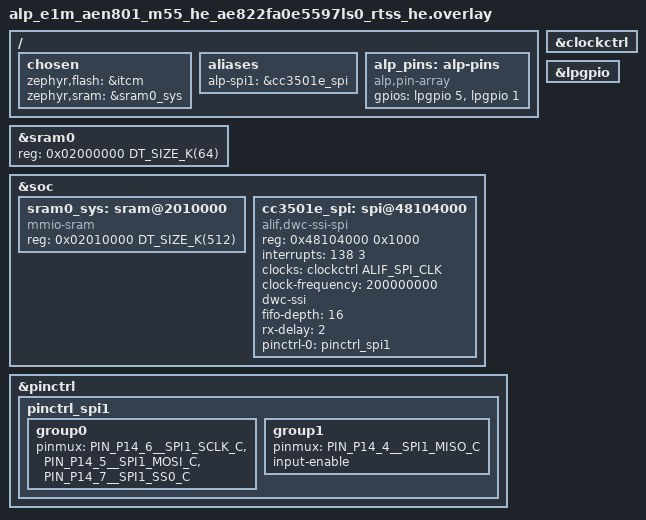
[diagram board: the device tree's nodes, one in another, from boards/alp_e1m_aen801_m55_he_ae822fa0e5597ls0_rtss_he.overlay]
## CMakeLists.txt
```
# SPDX-License-Identifier: Apache-2.0
#
# aen-cc3501e-socket-throughput -- measures CC3501E end-to-end TCP socket
# throughput over a correctly-sized window on the E1M-AEN801 (Ensemble E8,
# M55-HE). See src/main.c for why the window has to be this big.
#
# Standalone Zephyr app (no alp_project.py board.yaml flow), same shape as
# its closest sibling aen-cc3501e-command-sweep: build with
#   ZEPHYR_BASE=<zephyr-base> west build \
#     -b alp_e1m_aen801_m55_he/ae822fa0e5597ls0/rtss_he <this-dir> -- \
#     "-DEXTRA_ZEPHYR_MODULES=<alp-sdk>;<hal_alif>"
# Zephyr applies boards/<fully-qualified-board>.overlay by itself.

cmake_minimum_required(VERSION 3.20)

find_package(Zephyr REQUIRED HINTS $ENV{ZEPHYR_BASE})
project(aen_cc3501e_socket_throughput LANGUAGES C)

target_sources(app PRIVATE src/main.c)
# The SoM bring-up TEMPLATE (see its own header comment): opens the
# inter-chip SPI1 bridge + WIFI_EN/nRESET, enables the LP-pad output
# drivers pinctrl does not reach, binds the READY line, and runs the
# power + reset sequence. Copied verbatim from aen-cc3501e-command-sweep --
# byte-identical to the copies in every other aen-cc3501e-* sibling, same
# reasoning: a copyable template, not a cross-example reach-in.
target_sources(app PRIVATE src/cc3501e_bridge.c)
```

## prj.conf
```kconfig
# SPDX-License-Identifier: Apache-2.0
#
# Bench config for the CC3501E socket-throughput measurement on the
# E1M-AEN801 (Alif Ensemble E8, M55-HE). See src/main.c for what is measured
# and why the window is sized the way it is.

# --- Console -----------------------------------------------------------------
# Console: Alp UART console -- E1M edge UART0 (Alif UART5, P3_4/P3_5, 115200
# 8N1, NS16550), the E1M-AEN801 carrier console. The board _defconfig already
# selects it; set explicitly here so the app is self-describing.
CONFIG_SERIAL=y
CONFIG_CONSOLE=y
CONFIG_UART_CONSOLE=y
CONFIG_UART_INTERRUPT_DRIVEN=y
# Serial-less bench? Comment the four lines above and uncomment these to read
# 'ram_console_buf' over SWD instead -- the same toggle every sibling AEN
# bench app documents (see aen-rtc-tick-probe's prj.conf for the fuller note):
# CONFIG_RAM_CONSOLE=y
# CONFIG_RAM_CONSOLE_BUFFER_SIZE=4096
# CONFIG_UART_CONSOLE=n
CONFIG_PRINTK=y

# --- CC3501E bridge (SPI1 + WIFI_EN/nRESET/READY GPIOs) -----------------------
# The host-side chip driver (chips/cc3501e/*.c) plus the two peripheral
# classes it rides on: SPI for the inter-chip link (bus 1 -> the alp-spi1
# alias this app's overlay adds) and GPIO for WIFI_EN / nRESET / READY.
# Kconfig already enforces `depends on SPI && GPIO`; both are set explicitly
# here because this app has no board.yaml `peripherals:` block to generate
# them -- it is a standalone Zephyr app (see scripts/gen_example_alp_conf.py), same as
# aen-cc3501e-command-sweep. CONFIG_ALP_SDK_CHIP_CC3501E pulls in every
# chips/cc3501e/*.c TU (wifi/sockets/ble/gpio/spi/camera/power/ota/events),
# so this app can call cc3501e_wifi_connect()/cc3501e_sock_*() directly with
# no further Kconfig -- it never routes through the portable <alp/wifi.h>
# backend (CONFIG_ALP_SDK_WIFI_CC3501E), which attaches a DIFFERENT set of
# TUs this app has no use for.
CONFIG_SPI=y
CONFIG_GPIO=y
CONFIG_ALP_SDK=y
CONFIG_ALP_SDK_CHIP_CC3501E=y
# Pack 2 bytes per SPI FIFO slot on the polled bulk phases (#1725). The
# polled loop's MMIO accesses, not the 25 MHz wire, bound the bridge; the
# bits on the wire are identical. aen-cc3501e-bringup carries the same line.
CONFIG_SPI_DW_ALIF_PACK32=y

# CONFIG_ALP_SDK=y above defaults CONFIG_ALP_SDK_CONSOLE (zephyr/kconfigs/
# core.kconfig) to `y`, which `select`s CONFIG_SHELL -- pulling a `uart:~$`
# shell prompt into the middle of this app's own throughput transcript. This
# app never registers a shell command and never uses the `alp` console tree,
# so turn the console off explicitly rather than let its default drag the
# shell in unasked.
CONFIG_ALP_SDK_CONSOLE=n

# main()'s own locals + the HTTP header-scan state stay small: the recv
# buffer (SOCKTP_RECV_CEILING bytes, ~4 KB) and the cc3501e_t bridge handle
# (~32 KB, embeds several ALP_CC3501E_MAX_PAYLOAD scratch buffers) are BOTH
# STATIC in src/main.c, not automatic -- see that file's own header for why
# that discipline is load-bearing here, not optional: a sibling app in this
# tree died on its own prologue for exactly the mistake this app avoids by
# construction. 4096 matches aen-cc3501e-companion-tour, the other sibling
# that calls the socket API with the same static discipline.
CONFIG_MAIN_STACK_SIZE=4096

# Logging ON, deliberately -- a desynced SPI link reports its decisive fault
# via LOG_ERR in the upstream DesignWare SPI driver, and this app is a bench
# diagnostic, not a shipping image. LOG_MODE_MINIMAL keeps it deferred-free.
CONFIG_LOG=y
CONFIG_LOG_MODE_MINIMAL=y

# --- Memory/cache and optimisation: this app measures the link, so build it
# the way a product would run it (#2052) --------------------------------------
# D-cache ON is the board default (the M55's CPU_HAS_DCACHE), and the host side
# of the bridge is CPU-bound without it: with the cache off the polled payload
# loop reads its source from uncached SRAM and a 4092-byte STREAM_WRITE frame
# takes 4.7 ms instead of 1.3 ms, so the whole link runs at ~560 KB/s instead of
# ~1.27 MB/s (E1M-AEN803 2026W36-0009, 2026-09-29).  Older notes kept it off for
# a D-cache maintenance hang and for comparability with earlier cache-off runs;
# dozens of cache-on cold boots of this app on 2026-09-28/29 showed no hang.
# NOTE: scripts/bench/aen/aen-bench-shared.conf still forces CONFIG_DCACHE=n
# for every bench flow, so a Flow C measurement run must pass
# -DCONFIG_DCACHE=y on the west command line to get this app's real number.
CONFIG_DCACHE=y
# -O2, not -Os: -Os links picolibc's size-optimised libc whose memcpy/memset
# are byte loops, which cost the bridge ~0.15 ms per 4 KiB request (#2052).
CONFIG_SPEED_OPTIMIZATIONS=y
```

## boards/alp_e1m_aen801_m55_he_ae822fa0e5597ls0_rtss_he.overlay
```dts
/*
 * Copyright (c) 2026 Alp Lab AB
 * SPDX-License-Identifier: Apache-2.0
 *
 * aen-cc3501e-socket-throughput -- app overlay for the E1M-AEN801 (Alif
 * Ensemble E8, M55-HE), bench RAM-run via J-Link.
 *
 * Everything below is transcribed from aen-evk-demo's phase-8 overlay block
 * (see that file's own header for the full derivation behind every value
 * here), reused byte-for-byte via aen-cc3501e-command-sweep -- the sibling
 * app this one copies its bring-up template AND its memory placement from
 * (see src/cc3501e_bridge.h and that app's own overlay header, which this
 * app's own numbers must stay comparable to). Trimmed to exactly what the
 * bridge needs: the SoM-internal Alif <-> CC3501E link (SPI1 hardware SS0,
 * the LP-GPIO island carrying WIFI_EN/nRESET, and the READY input), the
 * mandatory bench ITCM retarget, AND (see the block below, deliberately kept
 * even though no other phase's hardware needs it here) the SRAM0 system-RAM
 * placement -- this app's own SOCK_RECV throughput window is measured over
 * that exact SPI1 link, and a faster-than-intended cache/DTCM path would
 * inflate the reported rate on precisely the FIFO-refill axis this
 * measurement exists to characterise, making the number not comparable to
 * any other AEN801 bench run. None of aen-evk-demo's other thirteen phases'
 * OWN hardware (PWM LED, SD, Ethernet, I2S/PDM, JPEG) is declared here --
 * this app touches none of it, and carrying it would only risk a pad
 * conflict with the bridge pins.
 */
#include <zephyr/dt-bindings/pinctrl/alif-ensemble-pinctrl.h>
#include <zephyr/dt-bindings/gpio/gpio.h>

/*
 * ============================================================================
 * SYSTEM-RAM PLACEMENT -- MATCHES aen-evk-demo's phase 8, deliberately
 * ============================================================================
 *
 * This app trims aen-evk-demo's overlay down to exactly the SoM-internal
 * CC3501E bridge (see the block below) -- EXCEPT for this one piece, which
 * it keeps even though nothing else here needs it.
 *
 * aen-evk-demo's own overlay (see ITS header for the full derivation, which
 * this app does not repeat) documents that phase 8's SPI1 FIFO refill --
 * the SAME link this app's Part 2 clocks bulk STREAM_WRITE / SPI1_TRANSFER
 * frames over -- is the one phase sensitive to cache-on vs cache-off timing
 * on this silicon: a DesignWare SSI master that underruns its TX FIFO
 * deasserts its own chip-select mid-frame, and the demo runs from uncached
 * global SRAM0 with CONFIG_DCACHE=n (see prj.conf) rather than the M55's
 * tightly-coupled DTCM specifically to keep that FIFO-refill loop on the
 * same timing this silicon was bench-validated against.
 *
 * A throughput measurement over that link cannot run FASTER than the demo's
 * on precisely the axis the demo's own comment calls out -- that would not
 * be a number anyone else's AEN801 bench run could be compared against, it
 * would be measuring a different link. So this app carries the same
 * retarget, even though (unlike the demo) it has no Ethernet DMA rings or
 * JPEG buffers that need SRAM0 for their own reasons -- one disjoint 512 KiB
 * window is more than this app's own footprint needs, but a narrower
 * carve-out would only add a second constant to keep in sync with the demo
 * for no behavioural benefit.
 */
&sram0 {
	reg = <0x02000000 DT_SIZE_K(64)>;
};

&soc {
	/* Plain "mmio-sram", NOT "zephyr,memory-region" -- see aen-evk-demo's
	 * overlay for why a second memory-region-compatible node here would
	 * alias the linker region instead of extending it. */
	sram0_sys: sram@2010000 {
		compatible = "mmio-sram";
		reg = <0x02010000 DT_SIZE_K(512)>;
	};
};

/*
 * MANDATORY bench RAM-run retarget: run from ITCM so J-Link can loadbin+run
 * without programming MRAM, and drop the MCUboot code-partition fixup.
 * PATH-REFERENCE form (&itcm), NOT the <&itcm> phandle-array form -- the
 * phandle-array form yields CONFIG_FLASH_SIZE=0 and the image overflows the
 * (empty) FLASH region at link time. System RAM (zephyr,sram) is retargeted
 * separately, to &sram0_sys above -- see that block's header.
 */
/ {
	chosen {
		zephyr,flash = &itcm;
		/delete-property/ zephyr,code-partition;
		zephyr,sram = &sram0_sys;
	};
};

/*
 * ============================================================================
 * The SoM-internal Alif <-> CC3501E Wi-Fi/BLE bridge
 * ============================================================================
 *
 *     net          Alif pad       dir   CC3501E pad
 *     ----------   ------------   ---   ---------------------
 *     WIFI_EN      P15_5          out   (supply gate)
 *     E_WIFI.NRST  P15_1_FLEX     out   (reset)
 *     SPI1.SCK     P14_6          out   GPIO_27 (CC35 SPI0 slave)
 *     SPI1.MOSI    P14_5          out   GPIO_28
 *     SPI1.MISO    P14_4          in    GPIO_29
 *     SPI1.SS0     P14_7          out   CC35 SPI0 CSN
 *
 * READY (CC35 GPIO_17) is deliberately left off this table: on the R2
 * module this app targets it is NOT wired to Alif P2_6 -- P2_6 is E1M pad
 * AH7 / I2S1_SCLK (the EVK's Arduino CK_RST), a DIFFERENT net from GPIO_17
 * / E1M pad G3.  See the P2_6 comment further down and
 * chips/cc3501e/cc3501e_core.c's cc3501e_reply_gate() comment for the bench
 * evidence and how a board that genuinely wires it can opt in.
 *
 * SoM-INTERNAL fact (metadata/e1m_modules/aen/inter-chip.tsv), not an E1M
 * edge pad -- hence an app overlay, not the board tree.
 */
&pinctrl {
	/*
	 * SPI1 master on P14_6 (SCK) / P14_5 (MOSI) / P14_4 (MISO), plus the
	 * hardware SS0 chip-select on P14_7. SS0 is the dwc-ssi peripheral's
	 * OWN select -- not a GPIO bodge, not CS-less, not static-low: the
	 * master asserts and deasserts it per transfer, which is exactly what
	 * frames each phase of the bridge's request/reply exchange. Do NOT
	 * add cs-gpios here; that installs a software CS and breaks the
	 * framing the firmware side is built around.
	 *
	 * input-enable on MISO because on this SoC a pad's INPUT BUFFER is a
	 * PADCTRL bit that only pinctrl sets -- without it the pad never
	 * senses what the slave drives.
	 */
	pinctrl_spi1: pinctrl_spi1 {
		group0 {
			pinmux = <PIN_P14_6__SPI1_SCLK_C>, <PIN_P14_5__SPI1_MOSI_C>,
				 <PIN_P14_7__SPI1_SS0_C>;
		};
		group1 {
			pinmux = <PIN_P14_4__SPI1_MISO_C>;
			input-enable;
		};

	};
};

/* P2_6 (E1M AH7 / I2S1_SCLK) is NOT the CC3501E READY net on the R2 module this
 * bridge targets -- it is E1M pad AH7 / I2S1_SCLK, which the E1M EVK
 * carrier repurposes as the Arduino header's CK_RST (metadata/boards/
 * e1m-evk.yaml); the real READY net lands on E1M pad G3 / IO16 instead
 * (metadata/e1m_modules/aen/from-cc3501e.tsv). This app therefore does not
 * mux or input-enable P2_6, and does not wire fw->ready_pin -- see
 * src/cc3501e_bridge.c and chips/cc3501e/cc3501e_core.c's cc3501e_reply_gate()
 * comment. A board (or a hand-reworked r1 unit) that genuinely wires GPIO17
 * to P2_6 can opt back in: add a pinctrl group muxing PIN_P2_6__GPIO with
 * input-enable (applied inside pinctrl_spi1's single init pass, not a
 * standalone runtime one -- a second pinctrl pass after SPI1 is up killed
 * the bridge on silicon, aen-evk-demo bench-measured), enable &gpio2, add
 * an alp_pins entry for it, and set fw->ready_pin in
 * cc3501e_bridge_bringup().

/*
 * DWC_ssi SPI1 (AHB) -- the on-SoM CC3501E inter-chip link. Deliberately not
 * in ensemble_e8_peripherals.dtsi (which declares only the customer-facing
 * edge SPI0), so the consuming app declares it. reg 0x48104000 = the SPI1
 * base (+0x1000 per instance from spi0's 0x48103000).
 *
 * clock-frequency is REQUIRED, not decorative: without it spi_dw_alif's
 * configure takes the clock-control path, which fails -EINVAL for the
 * gateless dummy ALIF_SPI_CLK, and every transceive then returns
 * ALP_ERR_INVAL at zero SCLK. 200 MHz is the real SSI functional clock (E8
 * HWRM); BAUDR = clock-frequency / freq_hz, and cc3501e_bridge.h asks for
 * 25 MHz = /8.
 *
 * rx-delay: NOT what clocks the link -- src/cc3501e_bridge.c pokes
 * 0x48104000+0xf0 with CC3501E_BRIDGE_RX_SAMPLE_DLY right after
 * alp_spi_open() returns, and that constant (silicon-measured, see that
 * file's header) is what the bridge actually runs at. Kept at <2> anyway
 * because the poke is wrapped in `#if CC3501E_BRIDGE_RX_SAMPLE_DLY > 0` --
 * setting the constant to 0 does not mean "no delay", it means this
 * property is what survives.
 */
&clockctrl {
	status = "okay";
};

&soc {
	cc3501e_spi: spi@48104000 {
		compatible = "alif,dwc-ssi-spi";
		#address-cells = <1>;
		#size-cells = <0>;
		reg = <0x48104000 0x1000>;
		interrupts = <138 3>; /* BENCH-TBD: confirm SPI1 IRQ, same as aen-evk-demo */
		clocks = <&clockctrl ALIF_SPI_CLK>;
		clock-frequency = <200000000>;
		dwc-ssi;
		fifo-depth = <16>;
		rx-delay = <2>;
		pinctrl-0 = <&pinctrl_spi1>;
		pinctrl-names = "default";
		status = "okay";
	};
};

/*
 * The LP-GPIO island carries WIFI_EN (P15_5) and E_WIFI.NRST (P15_1_FLEX).
 * No pinctrl group is needed for their mux: P15_x function 0 -- the reset
 * default -- already IS LPGPIO. Turning the pads' OUTPUT DRIVERS on is a
 * separate matter and not a devicetree fact at all; see the raw PADCTRL
 * write in src/cc3501e_bridge.c and the comment above it.
 */
&lpgpio {
	status = "okay";
};

/ {
	aliases {
		/* bus_id 1 in alp_spi_open() -> this controller. */
		alp-spi1 = &cc3501e_spi;
	};

	/*
	 * Compact 2-entry control array for the SoM-internal CC3501E control
	 * nets, in the order cc3501e_bridge.h's CC3501E_BRIDGE_PIN_* indices
	 * expect. These are NOT E1M edge pads, so this app does not use the
	 * 52-slot positional E1M map; a production board file appends
	 * SoM-internal control nets after the E1M pad slots. No READY entry
	 * here -- see the P2_6 comment above &gpio2's removal further up.
	 *
	 * There must be exactly ONE "alp,pin-array" node in the tree -- a
	 * second one broke pin resolution outright on the aen-evk-demo bench
	 * (2026-08-26): the bridge failed as if WIFI_EN were absent, which
	 * reads like a hardware fault and is not one.
	 */
	alp_pins: alp-pins {
		compatible = "alp,pin-array";
		gpios = <&lpgpio 5 GPIO_ACTIVE_HIGH>, /* [0] WIFI_EN     (P15_5)      */
			<&lpgpio 1 GPIO_ACTIVE_HIGH>; /* [1] E_WIFI.NRST (P15_1_FLEX) */
	};
};
```

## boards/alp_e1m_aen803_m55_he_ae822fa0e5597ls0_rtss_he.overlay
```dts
/*
 * Copyright (c) 2026 Alp Lab AB
 * SPDX-License-Identifier: Apache-2.0
 *
 * aen-cc3501e-socket-throughput -- app overlay for the E1M-AEN803 (Alif
 * Ensemble E8, M55-HE), bench RAM-run via J-Link.
 *
 * Everything below is transcribed from aen-evk-demo's phase-8 overlay block
 * (see that file's own header for the full derivation behind every value
 * here), reused byte-for-byte via aen-cc3501e-command-sweep -- the sibling
 * app this one copies its bring-up template AND its memory placement from
 * (see src/cc3501e_bridge.h and that app's own overlay header, which this
 * app's own numbers must stay comparable to). Trimmed to exactly what the
 * bridge needs: the SoM-internal Alif <-> CC3501E link (SPI1 hardware SS0,
 * the LP-GPIO island carrying WIFI_EN/nRESET, and the READY input), the
 * mandatory bench ITCM retarget, AND (see the block below, deliberately kept
 * even though no other phase's hardware needs it here) the SRAM0 system-RAM
 * placement -- this app's own SOCK_RECV throughput window is measured over
 * that exact SPI1 link, and a faster-than-intended cache/DTCM path would
 * inflate the reported rate on precisely the FIFO-refill axis this
 * measurement exists to characterise, making the number not comparable to
 * any other AEN803 bench run. None of aen-evk-demo's other thirteen phases'
 * OWN hardware (PWM LED, SD, Ethernet, I2S/PDM, JPEG) is declared here --
 * this app touches none of it, and carrying it would only risk a pad
 * conflict with the bridge pins.
 */
#include <zephyr/dt-bindings/pinctrl/alif-ensemble-pinctrl.h>
#include <zephyr/dt-bindings/gpio/gpio.h>

/*
 * ============================================================================
 * SYSTEM-RAM PLACEMENT -- MATCHES aen-evk-demo's phase 8, deliberately
 * ============================================================================
 *
 * This app trims aen-evk-demo's overlay down to exactly the SoM-internal
 * CC3501E bridge (see the block below) -- EXCEPT for this one piece, which
 * it keeps even though nothing else here needs it.
 *
 * aen-evk-demo's own overlay (see ITS header for the full derivation, which
 * this app does not repeat) documents that phase 8's SPI1 FIFO refill --
 * the SAME link this app's Part 2 clocks bulk STREAM_WRITE / SPI1_TRANSFER
 * frames over -- is the one phase sensitive to cache-on vs cache-off timing
 * on this silicon: a DesignWare SSI master that underruns its TX FIFO
 * deasserts its own chip-select mid-frame, and the demo runs from uncached
 * global SRAM0 with CONFIG_DCACHE=n (see prj.conf) rather than the M55's
 * tightly-coupled DTCM specifically to keep that FIFO-refill loop on the
 * same timing this silicon was bench-validated against.
 *
 * A throughput measurement over that link cannot run FASTER than the demo's
 * on precisely the axis the demo's own comment calls out -- that would not
 * be a number anyone else's AEN803 bench run could be compared against, it
 * would be measuring a different link. So this app carries the same
 * retarget, even though (unlike the demo) it has no Ethernet DMA rings or
 * JPEG buffers that need SRAM0 for their own reasons -- one disjoint 512 KiB
 * window is more than this app's own footprint needs, but a narrower
 * carve-out would only add a second constant to keep in sync with the demo
 * for no behavioural benefit.
 */
&sram0 {
	reg = <0x02000000 DT_SIZE_K(64)>;
};

&soc {
	/* Plain "mmio-sram", NOT "zephyr,memory-region" -- see aen-evk-demo's
	 * overlay for why a second memory-region-compatible node here would
	 * alias the linker region instead of extending it. */
	sram0_sys: sram@2010000 {
		compatible = "mmio-sram";
		reg = <0x02010000 DT_SIZE_K(512)>;
	};
};

/*
 * MANDATORY bench RAM-run retarget: run from ITCM so J-Link can loadbin+run
 * without programming MRAM, and drop the MCUboot code-partition fixup.
 * PATH-REFERENCE form (&itcm), NOT the <&itcm> phandle-array form -- the
 * phandle-array form yields CONFIG_FLASH_SIZE=0 and the image overflows the
 * (empty) FLASH region at link time. System RAM (zephyr,sram) is retargeted
 * separately, to &sram0_sys above -- see that block's header.
 */
/ {
	chosen {
		zephyr,flash = &itcm;
		/delete-property/ zephyr,code-partition;
		zephyr,sram = &sram0_sys;
	};
};

/*
 * ============================================================================
 * The SoM-internal Alif <-> CC3501E Wi-Fi/BLE bridge
 * ============================================================================
 *
 *     net          Alif pad       dir   CC3501E pad
 *     ----------   ------------   ---   ---------------------
 *     WIFI_EN      P15_5          out   (supply gate)
 *     E_WIFI.NRST  P15_1_FLEX     out   (reset)
 *     SPI1.SCK     P14_6          out   GPIO_27 (CC35 SPI0 slave)
 *     SPI1.MOSI    P14_5          out   GPIO_28
 *     SPI1.MISO    P14_4          in    GPIO_29
 *     SPI1.SS0     P14_7          out   CC35 SPI0 CSN
 *
 * READY (CC35 GPIO_17) is deliberately left off this table: on the R2
 * module this app targets it is NOT wired to Alif P2_6 -- P2_6 is E1M pad
 * AH7 / I2S1_SCLK (the EVK's Arduino CK_RST), a DIFFERENT net from GPIO_17
 * / E1M pad G3.  See the P2_6 comment further down and
 * chips/cc3501e/cc3501e_core.c's cc3501e_reply_gate() comment for the bench
 * evidence and how a board that genuinely wires it can opt in.
 *
 * SoM-INTERNAL fact (metadata/e1m_modules/aen/inter-chip.tsv), not an E1M
 * edge pad -- hence an app overlay, not the board tree.
 */
&pinctrl {
	/*
	 * SPI1 master on P14_6 (SCK) / P14_5 (MOSI) / P14_4 (MISO), plus the
	 * hardware SS0 chip-select on P14_7. SS0 is the dwc-ssi peripheral's
	 * OWN select -- not a GPIO bodge, not CS-less, not static-low: the
	 * master asserts and deasserts it per transfer, which is exactly what
	 * frames each phase of the bridge's request/reply exchange. Do NOT
	 * add cs-gpios here; that installs a software CS and breaks the
	 * framing the firmware side is built around.
	 *
	 * input-enable on MISO because on this SoC a pad's INPUT BUFFER is a
	 * PADCTRL bit that only pinctrl sets -- without it the pad never
	 * senses what the slave drives.
	 */
	pinctrl_spi1: pinctrl_spi1 {
		group0 {
			pinmux = <PIN_P14_6__SPI1_SCLK_C>, <PIN_P14_5__SPI1_MOSI_C>,
				 <PIN_P14_7__SPI1_SS0_C>;
		};
		group1 {
			pinmux = <PIN_P14_4__SPI1_MISO_C>;
			input-enable;
		};

	};
};

/* P2_6 (E1M AH7 / I2S1_SCLK) is NOT the CC3501E READY net on the R2 module this
 * bridge targets -- it is E1M pad AH7 / I2S1_SCLK, which the E1M EVK
 * carrier repurposes as the Arduino header's CK_RST (metadata/boards/
 * e1m-evk.yaml); the real READY net lands on E1M pad G3 / IO16 instead
 * (metadata/e1m_modules/aen/from-cc3501e.tsv). This app therefore does not
 * mux or input-enable P2_6, and does not wire fw->ready_pin -- see
 * src/cc3501e_bridge.c and chips/cc3501e/cc3501e_core.c's cc3501e_reply_gate()
 * comment. A board (or a hand-reworked r1 unit) that genuinely wires GPIO17
 * to P2_6 can opt back in: add a pinctrl group muxing PIN_P2_6__GPIO with
 * input-enable (applied inside pinctrl_spi1's single init pass, not a
 * standalone runtime one -- a second pinctrl pass after SPI1 is up killed
 * the bridge on silicon, aen-evk-demo bench-measured), enable &gpio2, add
 * an alp_pins entry for it, and set fw->ready_pin in
 * cc3501e_bridge_bringup().

/*
 * DWC_ssi SPI1 (AHB) -- the on-SoM CC3501E inter-chip link. Deliberately not
 * in ensemble_e8_peripherals.dtsi (which declares only the customer-facing
 * edge SPI0), so the consuming app declares it. reg 0x48104000 = the SPI1
 * base (+0x1000 per instance from spi0's 0x48103000).
 *
 * clock-frequency is REQUIRED, not decorative: without it spi_dw_alif's
 * configure takes the clock-control path, which fails -EINVAL for the
 * gateless dummy ALIF_SPI_CLK, and every transceive then returns
 * ALP_ERR_INVAL at zero SCLK. 200 MHz is the real SSI functional clock (E8
 * HWRM); BAUDR = clock-frequency / freq_hz, and cc3501e_bridge.h asks for
 * 25 MHz = /8.
 *
 * rx-delay: NOT what clocks the link -- src/cc3501e_bridge.c pokes
 * 0x48104000+0xf0 with CC3501E_BRIDGE_RX_SAMPLE_DLY right after
 * alp_spi_open() returns, and that constant (silicon-measured, see that
 * file's header) is what the bridge actually runs at. Kept at <2> anyway
 * because the poke is wrapped in `#if CC3501E_BRIDGE_RX_SAMPLE_DLY > 0` --
 * setting the constant to 0 does not mean "no delay", it means this
 * property is what survives.
 */
&clockctrl {
	status = "okay";
};

&soc {
	cc3501e_spi: spi@48104000 {
		compatible = "alif,dwc-ssi-spi";
		#address-cells = <1>;
		#size-cells = <0>;
		reg = <0x48104000 0x1000>;
		interrupts = <138 3>; /* BENCH-TBD: confirm SPI1 IRQ, same as aen-evk-demo */
		clocks = <&clockctrl ALIF_SPI_CLK>;
		clock-frequency = <200000000>;
		dwc-ssi;
		fifo-depth = <16>;
		rx-delay = <2>;
		pinctrl-0 = <&pinctrl_spi1>;
		pinctrl-names = "default";
		status = "okay";
	};
};

/*
 * The LP-GPIO island carries WIFI_EN (P15_5) and E_WIFI.NRST (P15_1_FLEX).
 * No pinctrl group is needed for their mux: P15_x function 0 -- the reset
 * default -- already IS LPGPIO. Turning the pads' OUTPUT DRIVERS on is a
 * separate matter and not a devicetree fact at all; see the raw PADCTRL
 * write in src/cc3501e_bridge.c and the comment above it.
 */
&lpgpio {
	status = "okay";
};

/ {
	aliases {
		/* bus_id 1 in alp_spi_open() -> this controller. */
		alp-spi1 = &cc3501e_spi;
	};

	/*
	 * Compact 2-entry control array for the SoM-internal CC3501E control
	 * nets, in the order cc3501e_bridge.h's CC3501E_BRIDGE_PIN_* indices
	 * expect. These are NOT E1M edge pads, so this app does not use the
	 * 52-slot positional E1M map; a production board file appends
	 * SoM-internal control nets after the E1M pad slots. No READY entry
	 * here -- see the P2_6 comment above &gpio2's removal further up.
	 *
	 * There must be exactly ONE "alp,pin-array" node in the tree -- a
	 * second one broke pin resolution outright on the aen-evk-demo bench
	 * (2026-08-26): the bridge failed as if WIFI_EN were absent, which
	 * reads like a hardware fault and is not one.
	 */
	alp_pins: alp-pins {
		compatible = "alp,pin-array";
		gpios = <&lpgpio 5 GPIO_ACTIVE_HIGH>, /* [0] WIFI_EN     (P15_5)      */
			<&lpgpio 1 GPIO_ACTIVE_HIGH>; /* [1] E_WIFI.NRST (P15_1_FLEX) */
	};
};
```

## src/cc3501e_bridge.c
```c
/*
 * SPDX-License-Identifier: Apache-2.0
 * Copyright 2026 Alp Lab AB
 *
 * E1M-AEN SoM CC3501E bridge bring-up helper -- see cc3501e_bridge.h.
 *
 * The final reset is warm-aware.  cc3501e_reset() drops WIFI_EN for 50 ms, a
 * supply cold cycle; on a CC3501E that is already running (an activated unit with
 * vendor_sbl_container_enable=1 may then never relaunch) that must not happen on a
 * mere re-run or warm reset of the application.  So when WIFI_EN already reads high
 * AND the chip answers a PING the bring-up resets through nRESET only
 * (cc3501e_hard_reset()), and uses cc3501e_reset() only from WIFI_EN low or, as a
 * last resort, from a chip that stays silent through an nRESET-only reset.  WIFI_EN
 * reading high alone is not trusted: a pull-up would make every power-on look warm
 * (whether the module has one is an open question, issue #2797).
 */

#include "cc3501e_bridge.h"

#include <stdio.h>

#if defined(CONFIG_SOC_AE822FA0E5597LS0_RTSS_HE) || defined(CONFIG_SOC_AE822FA0E5597LS0_RTSS_HP)
#include <zephyr/arch/cpu.h>
#include <zephyr/devicetree.h>
#include <zephyr/sys/sys_io.h>
/*
 * AEN LP-pad mux (Alif Ensemble E8, both M55-HE and M55-HP cores).  WIFI_EN
 * (P15_5) and nRESET (P15_1) are on the Alif LP-GPIO island, bound by the
 * generic snps,designware-gpio driver which does NOT apply Alif pinctrl --
 * so the LP pads stay un-muxed and their output drivers OFF (confirmed on
 * silicon on M55-HE: WIFI_EN never powers the CC3501E until these regs are
 * set).  0x23 = the Alif GPIO-output pad config (driver + read-enable +
 * drive strength).  TODO: drop this raw poke once the Alif GPIO backend
 * muxes the LP island via pinctrl.
 *
 * ALIF_LPGPIO_PADCTRL_BASE (0x42007000) is not an M55-HE-local address: the
 * shared upstream `pin-controller@1a603000` node (ensemble_common.dtsi,
 * included by both cores' SoC dtsi) declares this exact window as its
 * second `reg` range, and `alp_e1m_aen801_m55_hp-pinctrl.dtsi` already
 * muxes a different LP-GPIO pad (P15_0, RTC_ALARM) from the M55-HP pinctrl
 * driver through it, so the poke below is equally applicable on M55-HP.
 * Running it on M55-HP is NOT bench-proven -- only running it on M55-HE has
 * been confirmed on silicon.
 */
#define ALIF_LPGPIO_PADCTRL_BASE 0x42007000u
#define ALIF_PAD_GPIO_OUTPUT     0x23u
/* Latch an LP-GPIO pin HIGH in the port's data register while the pad is still an
 * INPUT.  Switching the direction afterwards then drives the already-high level; the
 * other order (direction first, value second -- what gpio_dw's configure does even
 * with an init flag) drives whatever DR holds, and after an LP-GPIO reset that is 0:
 * a glitch on WIFI_EN (P15_5, bit 5) drops the supply of a running chip, one on
 * nRESET (P15_1, bit 1) asserts its reset.  DR is written directly (read-modify-write, the
 * same access gpio_dw's port_set_bits_raw makes) so this template stays on the
 * portable <alp/...> headers: SWPORTA_DR is offset 0x00 of the DesignWare GPIO block
 * (zephyr drivers/gpio/gpio_dw_registers.h), the block base is the `lpgpio` node's
 * reg, and the LP-GPIO clock is already on because alp_gpio_open() opened the pin. */
#define DW_GPIO_SWPORTA_DR 0x00u
static void aen_lp_gpio_latch_high(unsigned int bit)
{
	const mem_addr_t dr = DT_REG_ADDR(DT_NODELABEL(lpgpio)) + DW_GPIO_SWPORTA_DR;

	sys_write32(sys_read32(dr) | (1u << bit), dr);
}

static void aen_lp_pads_enable_output(void)
{
	sys_write32(ALIF_PAD_GPIO_OUTPUT, ALIF_LPGPIO_PADCTRL_BASE + 5u * 4u); /* P15_5 WIFI_EN */
	sys_write32(ALIF_PAD_GPIO_OUTPUT, ALIF_LPGPIO_PADCTRL_BASE + 1u * 4u); /* P15_1 nRESET  */
}
#else
static inline void aen_lp_pads_enable_output(void)
{
}
static inline void aen_lp_gpio_latch_high(unsigned int bit)
{
	(void)bit;
}
#endif

alp_status_t cc3501e_bridge_bringup(cc3501e_t *fw)
{
	if (fw == NULL) {
		return ALP_ERR_INVAL;
	}

	/* 1. Control pins: WIFI_EN (supply gate) + nRESET.  These are Alif LP-GPIO
	 *    pads, not E1M edge pads -- the SoM owns them. */
	alp_gpio_t *wifi_en = alp_gpio_open(CC3501E_BRIDGE_PIN_WIFI_EN);
	alp_gpio_t *nrst    = alp_gpio_open(CC3501E_BRIDGE_PIN_NRST);
	if (wifi_en == NULL || nrst == NULL) {
		if (wifi_en != NULL) {
			alp_gpio_close(wifi_en);
		}
		if (nrst != NULL) {
			alp_gpio_close(nrst);
		}
		return ALP_ERR_NOT_PRESENT_ON_THIS_SOC;
	}
	aen_lp_pads_enable_output();
	/* Sample the supply gate BEFORE touching its direction.  High is only a HINT
	 * that the chip may be powered -- an external pull-up on WIFI_EN would make every
	 * power-on read high (whether the module has one is an OPEN QUESTION; the
	 * netlist has not been checked), so the decision below also needs a PING. */
	bool wifi_was_high = false;
	/* A failed read leaves the level unknown: never take the supply-cycling cold path
	 * on that alone -- go through the PING path below, which still ends in
	 * cc3501e_reset() if the chip turns out to be silent. */
	const bool wifi_unknown = alp_gpio_read(wifi_en, &wifi_was_high) != ALP_OK;
	if (wifi_was_high || wifi_unknown) {
		/* Latch the level in DR first so the direction change cannot glitch it low.  An
		 * unknown level is latched high too: DR bit 5 = 0 would otherwise drop the supply
		 * of a chip that is already running the moment the pin becomes an output. */
		aen_lp_gpio_latch_high(5u); /* P15_5 WIFI_EN */
	}
	/* Same for nRESET: a running chip has it released (high).  Without the latch the
	 * direction change below drives DR bit 1 = 0 and holds the chip in reset, so the
	 * warm PING always fails and the bring-up falls through to a WIFI_EN supply cycle. */
	bool nrst_was_high = false;
	if (alp_gpio_read(nrst, &nrst_was_high) == ALP_OK && nrst_was_high) {
		aen_lp_gpio_latch_high(1u); /* P15_1 nRESET */
	}
	(void)alp_gpio_configure(wifi_en, ALP_GPIO_OUTPUT, ALP_GPIO_PULL_NONE);
	(void)alp_gpio_configure(nrst, ALP_GPIO_OUTPUT, ALP_GPIO_PULL_NONE);

	/* 2. Inter-chip SPI (Alif = master).  CS is the dwc-ssi hardware SS0
	 *    muxed on P14_7; the app passes ALP_SPI_NO_CS so no software GPIO CS
	 *    is installed and the SPI controller drives SS0 per transfer.  Mode 0
	 *    matches the CC3501E vendor image frameFormat. */
	alp_spi_t *spi = alp_spi_open(&(alp_spi_config_t){
	    .bus_id        = CC3501E_BRIDGE_SPI_BUS_ID,
	    .freq_hz       = CC3501E_BRIDGE_SPI_FREQ_HZ,
	    .mode          = ALP_SPI_MODE_0,
	    .bits_per_word = 8u,
	    .cs_pin_id     = ALP_SPI_NO_CS,
	});
	if (spi == NULL) {
		alp_gpio_close(wifi_en);
		alp_gpio_close(nrst);
		return ALP_ERR_NOT_PRESENT_ON_THIS_SOC;
	}

#if CC3501E_BRIDGE_RX_SAMPLE_DLY > 0
	/* Raise the SCLK past 1 MHz: the DW SSI RX_SAMPLE_DLY register (0xf0) delays
	 * the MISO capture point by N ssi_clk cycles to cover the on-SoM trace + crossed
	 * data round-trip.  Zephyr spi_dw never writes it (leaves 0), so without this
	 * >1 MHz mis-samples MISO (cold reqhdr_rx=0xFFFFFFFF).  Written with SSI disabled
	 * (SSIENR=0); persists across the driver's per-transfer configure.  Value is
	 * silicon-tuned -- sweep CC3501E_BRIDGE_RX_SAMPLE_DLY at the target SCLK.
	 *
	 * SWEEP TRAP -- read before setting the constant to 0: the `#if > 0` above
	 * compiles this block out, so 0 does not mean "no delay", it means the SPI
	 * node's `rx-delay` devicetree value is left in place.  aen-cc3501e-bringup
	 * and aen-evk-demo declare rx-delay = <2>, so a naive N=0 sweep point on
	 * those two silently measures 2.  Read 0x481040F0 back to see what the link
	 * is actually running at. */
	{
		volatile uint32_t *ssienr =
		    (volatile uint32_t *)(uintptr_t)(CC3501E_BRIDGE_SPI1_BASE + 0x08u);
		volatile uint32_t *rsd = (volatile uint32_t *)(uintptr_t)(CC3501E_BRIDGE_SPI1_BASE + 0xf0u);
		uint32_t           en  = *ssienr;
		*ssienr                = 0u;
		*rsd                   = (uint32_t)CC3501E_BRIDGE_RX_SAMPLE_DLY;
		*ssienr                = en;
	}
#endif

	/* 3. Bind the bus + control pins; attach the GPIO proxy (proxied E1M IOs then
	 *    route over the bridge); run the power + reset sequence (TI SWRU626 + the
	 *    Puya cold-boot hard-reset workaround).  Leaves WIFI_EN HIGH. */
	(void)cc3501e_init(fw, spi);
	fw->enable_pin = wifi_en;
	fw->reset_pin  = nrst;
	/* READY (CC35 GPIO17) is NOT wired here by default on this R2 module --
	 * see chips/cc3501e/cc3501e_core.c's cc3501e_reply_gate() comment for the
	 * pin-routing fact, the bench evidence, and how a board that genuinely
	 * wires it can opt back in via fw->ready_pin. */
#ifdef CONFIG_ALP_SDK_GPIO_CC3501E_PROXY
	(void)alp_gpio_cc3501e_attach(fw);
#endif
#ifdef CONFIG_ALP_SDK_WIFI_CC3501E
	(void)alp_wifi_cc3501e_attach(fw);
#endif
#ifdef CONFIG_ALP_SDK_BLE_CC3501E
	(void)alp_ble_cc3501e_attach(fw);
#endif
	/* One line naming the path taken, so a log shows whether the supply was cycled. */
	if (!wifi_was_high && !wifi_unknown) {
		printf("[cc3501e_bridge] WIFI_EN low: cold power-up (cc3501e_reset)\n");
		return cc3501e_reset(fw); /* supply low: the full cold-boot sequence */
	}
	/* WIFI_EN reads high.  Warm = the chip ANSWERS a PING; a pull-up alone proves
	 * nothing.  Warm: nRESET only, never a WIFI_EN toggle. */
	if (cc3501e_ping(fw) == ALP_OK) {
		printf("[cc3501e_bridge] WIFI_EN high, PING ok: warm, nRESET only\n");
		return cc3501e_hard_reset(fw);
	}
	/* High but silent: powered-and-hung, or unpowered behind a pull-up.  Try the
	 * nRESET-only reset first (safe for a powered chip); only if the chip still does
	 * not answer is the supply cycled -- the last resort, taken from a chip that is
	 * already unresponsive. */
	if (cc3501e_hard_reset(fw) == ALP_OK && cc3501e_ping(fw) == ALP_OK) {
		printf("[cc3501e_bridge] WIFI_EN high, silent: recovered by nRESET only\n");
		return ALP_OK;
	}
	printf("[cc3501e_bridge] WIFI_EN high, silent after nRESET: supply cycle (cc3501e_reset)\n");
	return cc3501e_reset(fw);
}
```
